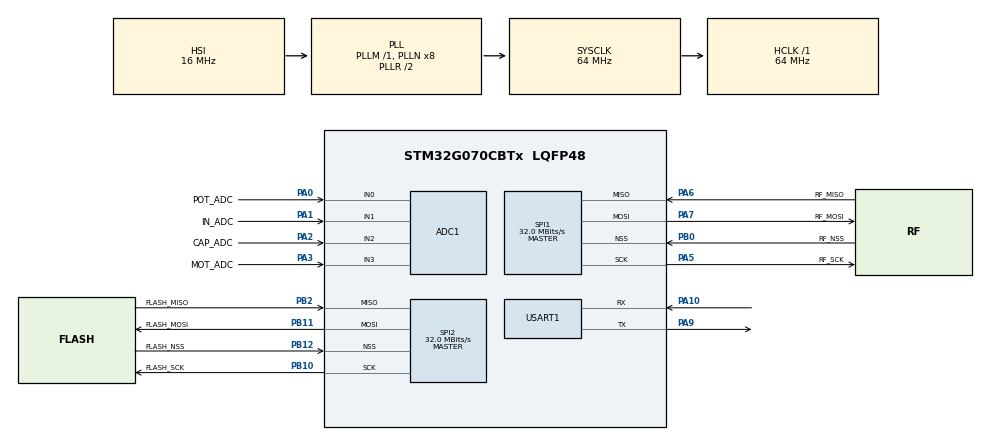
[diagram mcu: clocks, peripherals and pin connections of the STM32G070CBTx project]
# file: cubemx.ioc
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ADC1.AWD1HighThreshold=4095
ADC1.AWD1ITMode=ENABLE
ADC1.ContinuousConvMode=ENABLE
ADC1.DMAContinuousRequests=ENABLE
ADC1.EOCSelection=ADC_EOC_SINGLE_CONV
ADC1.EnableAnalogWatchDog1=true
ADC1.NbrOfConversion=1
ADC1.NbrOfConversionFlag=0
ADC1.Overrun=ADC_OVR_DATA_OVERWRITTEN
ADC1.SamplingTimeCommon1=ADC_SAMPLETIME_160CYCLES_5
ADC1.SelectedChannel=ADC_CHANNEL_0|ADC_CHANNEL_1|ADC_CHANNEL_2|ADC_CHANNEL_3
ADC1.Sequencer=NOT_FULLY_CONFIGURABLE
ADC1.WatchdogMode=ADC_ANALOGWATCHDOG_ALL_REG
ADC1.master=1
Dma.ADC1.0.Direction=DMA_PERIPH_TO_MEMORY
Dma.ADC1.0.EventEnable=DISABLE
Dma.ADC1.0.Instance=DMA1_Channel1
Dma.ADC1.0.MemDataAlignment=DMA_MDATAALIGN_WORD
Dma.ADC1.0.MemInc=DMA_MINC_ENABLE
Dma.ADC1.0.Mode=DMA_CIRCULAR
Dma.ADC1.0.PeriphDataAlignment=DMA_PDATAALIGN_WORD
Dma.ADC1.0.PeriphInc=DMA_PINC_DISABLE
Dma.ADC1.0.Polarity=HAL_DMAMUX_REQ_GEN_RISING
Dma.ADC1.0.Priority=DMA_PRIORITY_LOW
Dma.ADC1.0.RequestNumber=1
Dma.ADC1.0.SignalID=NONE
Dma.ADC1.0.SyncEnable=ENABLE
Dma.ADC1.0.SyncPolarity=HAL_DMAMUX_SYNC_RISING
Dma.ADC1.0.SyncRequestNumber=1
Dma.ADC1.0.SyncSignalID=NONE
Dma.Request0=ADC1
IWDG.Prescaler=IWDG_PRESCALER_256
Mcu.Family=STM32G0
Mcu.Name=STM32G070CBTx
Mcu.Package=LQFP48
NVIC.ADC1_IRQn=true\:0\:0\:false\:false\:true\:true\:true\:true
NVIC.DMA1_Ch4_7_DMAMUX1_OVR_IRQn=true\:0\:0\:false\:false\:true\:false\:true\:true
NVIC.DMA1_Channel1_IRQn=true\:0\:0\:false\:false\:true\:false\:true\:true
NVIC.RTC_TAMP_IRQn=true\:0\:0\:false\:false\:true\:true\:true\:true
NVIC.SPI1_IRQn=true\:0\:0\:false\:false\:true\:true\:true\:true
PA0.GPIO_Label=POT_ADC
PA0.Mode=IN0
PA0.Signal=ADC1_IN0
PA1.GPIO_Label=IN_ADC
PA1.Mode=IN1
PA1.Signal=ADC1_IN1
PA10.Mode=Asynchronous
PA10.Signal=USART1_RX
PA13.Mode=Serial_Wire
PA13.Signal=SYS_SWDIO
PA14-BOOT0.Mode=Serial_Wire
PA14-BOOT0.Signal=SYS_SWCLK
PA2.GPIO_Label=CAP_ADC
PA2.Mode=IN2
PA2.Signal=ADC1_IN2
PA3.GPIO_Label=MOT_ADC
PA3.Mode=IN3
PA3.Signal=ADC1_IN3
PA5.GPIO_Label=RF_SCK
PA5.Mode=Full_Duplex_Master
PA5.Signal=SPI1_SCK
PA6.GPIO_Label=RF_MISO
PA6.Mode=Full_Duplex_Master
PA6.Signal=SPI1_MISO
PA7.GPIO_Label=RF_MOSI
PA7.Mode=Full_Duplex_Master
PA7.Signal=SPI1_MOSI
PA9.Mode=Asynchronous
PA9.Signal=USART1_TX
PB0.GPIO_Label=RF_NSS
PB0.Mode=NSS_Signal_Hard_Input
PB0.Signal=SPI1_NSS
PB10.GPIO_Label=FLASH_SCK
PB10.Mode=Full_Duplex_Master
PB10.Signal=SPI2_SCK
PB11.GPIO_Label=FLASH_MOSI
PB11.Mode=Full_Duplex_Master
PB11.Signal=SPI2_MOSI
PB12.GPIO_Label=FLASH_NSS
PB12.Mode=NSS_Signal_Hard_Input
PB12.Signal=SPI2_NSS
PB2.GPIO_Label=FLASH_MISO
PB2.Mode=Full_Duplex_Master
PB2.Signal=SPI2_MISO
PC14-OSC32_IN\ (PC14).Mode=LSE-External-Oscillator
PC14-OSC32_IN\ (PC14).Signal=RCC_OSC32_IN
PC15-OSC32_OUT\ (PC15).Mode=LSE-External-Oscillator
PC15-OSC32_OUT\ (PC15).Signal=RCC_OSC32_OUT
ProjectManager.HeapSize=0x200
ProjectManager.StackSize=0x400
ProjectManager.TargetToolchain=EWARM V8.50
RCC.ADCFreq_Value=64000000
RCC.AHBFreq_Value=64000000
RCC.CortexFreq_Value=64000000
RCC.EXTERNAL_CLOCK_VALUE=48000
RCC.HCLKFreq_Value=64000000
RCC.HSE_VALUE=8000000
RCC.HSI_VALUE=16000000
RCC.RTCClockSelection=RCC_RTCCLKSOURCE_LSE
RCC.SYSCLKFreq_VALUE=64000000
RCC.SYSCLKSource=RCC_SYSCLKSOURCE_PLLCLK
RCC.VCOOutputFreq_Value=128000000
RTC.Alarm-Alarm\ A=RTC_ALARM_A
RTC.AlarmDateWeekDaySel-Alarm\ A=RTC_ALARMDATEWEEKDAYSEL_WEEKDAY
RTC.Date=24
RTC.Format=RTC_FORMAT_BIN
RTC.HourFormat=RTC_HOURFORMAT_12
RTC.Hours_A-Alarm\ A=1
RTC.Month=RTC_MONTH_FEBRUARY
RTC.WeekDay=RTC_WEEKDAY_TUESDAY
RTC.Year=20
SPI1.CalculateBaudRate=32.0 MBits/s
SPI1.Direction=SPI_DIRECTION_2LINES
SPI1.Mode=SPI_MODE_MASTER
SPI1.VirtualNSS=VM_NSSHARD
SPI1.VirtualType=VM_MASTER
SPI2.CalculateBaudRate=32.0 MBits/s
SPI2.Direction=SPI_DIRECTION_2LINES
SPI2.Mode=SPI_MODE_MASTER
SPI2.VirtualNSS=VM_NSSHARD
SPI2.VirtualType=VM_MASTER
USART1.VirtualMode-Asynchronous=VM_ASYNC
VP_IWDG_VS_IWDG.Mode=IWDG_Activate
VP_RTC_VS_RTC_Activate.Mode=RTC_Enabled
VP_RTC_VS_RTC_Alarm_A_Intern.Mode=Alarm A
VP_RTC_VS_RTC_Calendar.Mode=RTC_Calendar
VP_SYS_VS_DBSignals.Mode=DisableDeadBatterySignals
board=custom

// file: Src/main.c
/* USER CODE BEGIN Header */
/**
  ******************************************************************************
  * @file           : main.c
  * @brief          : Main program body
  ******************************************************************************
  * @attention
  *
  * Copyright (c) 2023 STMicroelectronics.
  * All rights reserved.
  *
  * This software is licensed under terms that can be found in the LICENSE file
  * in the root directory of this software component.
  * If no LICENSE file comes with this software, it is provided AS-IS.
  *
  ******************************************************************************
  */
/* USER CODE END Header */
#include "main.h"
#include "adc.h"
#include "dma.h"
#include "iwdg.h"
#include "rtc.h"
#include "spi.h"
#include "usart.h"
#include "gpio.h"

/* USER CODE BEGIN Includes */
#include <rtthread.h>
#include "drv_common.h"

#define DBG_TAG "main"
#define DBG_LVL DBG_LOG
#include <rtdbg.h>
/* USER CODE END Includes */

void SystemClock_Config(void);

__WEAK int main(void)
{

  /* MCU Configuration--------------------------------------------------------*/

  /* Reset of all peripherals, Initializes the Flash interface and the Systick. */
  HAL_Init();

  /* Configure the system clock */
  SystemClock_Config();

  /* Initialize all configured peripherals */
  MX_GPIO_Init();
  MX_DMA_Init();
  MX_ADC1_Init();
  MX_RTC_Init();
  MX_USART1_UART_Init();
  MX_SPI1_Init();
  MX_SPI2_Init();
  MX_IWDG_Init();

  /* Infinite loop */
  /* USER CODE BEGIN WHILE */
  while (1)
  {

      LOG_D("Hello RT-Thread!");
      rt_thread_mdelay(1000);
    /* USER CODE END WHILE */

  }
}

void SystemClock_Config(void)
{
  RCC_OscInitTypeDef RCC_OscInitStruct = {0};
  RCC_ClkInitTypeDef RCC_ClkInitStruct = {0};
//  RCC_PeriphCLKInitTypeDef PeriphClkInit = {0};

  /** Configure the main internal regulator output voltage
  */
  HAL_PWREx_ControlVoltageScaling(PWR_REGULATOR_VOLTAGE_SCALE1);

  /** Configure LSE Drive Capability
  */
  HAL_PWR_EnableBkUpAccess();
  __HAL_RCC_LSEDRIVE_CONFIG(RCC_LSEDRIVE_LOW);

  /** Initializes the RCC Oscillators according to the specified parameters
  * in the RCC_OscInitTypeDef structure.
  */
  RCC_OscInitStruct.OscillatorType = RCC_OSCILLATORTYPE_HSI|RCC_OSCILLATORTYPE_LSE;
  RCC_OscInitStruct.LSEState = RCC_LSE_ON;
  RCC_OscInitStruct.HSIState = RCC_HSI_ON;
  RCC_OscInitStruct.HSIDiv = RCC_HSI_DIV1;
  RCC_OscInitStruct.HSICalibrationValue = RCC_HSICALIBRATION_DEFAULT;
  RCC_OscInitStruct.PLL.PLLState = RCC_PLL_ON;
  RCC_OscInitStruct.PLL.PLLSource = RCC_PLLSOURCE_HSI;
  RCC_OscInitStruct.PLL.PLLM = RCC_PLLM_DIV1;
  RCC_OscInitStruct.PLL.PLLN = 8;
  RCC_OscInitStruct.PLL.PLLP = RCC_PLLP_DIV2;
  RCC_OscInitStruct.PLL.PLLR = RCC_PLLR_DIV2;
  if (HAL_RCC_OscConfig(&RCC_OscInitStruct) != HAL_OK)
  {
    Error_Handler();
  }

  /** Initializes the CPU, AHB and APB buses clocks
  */
  RCC_ClkInitStruct.ClockType = RCC_CLOCKTYPE_HCLK|RCC_CLOCKTYPE_SYSCLK
                              |RCC_CLOCKTYPE_PCLK1;
  RCC_ClkInitStruct.SYSCLKSource = RCC_SYSCLKSOURCE_PLLCLK;
  RCC_ClkInitStruct.AHBCLKDivider = RCC_SYSCLK_DIV1;
  RCC_ClkInitStruct.APB1CLKDivider = RCC_HCLK_DIV1;

  if (HAL_RCC_ClockConfig(&RCC_ClkInitStruct, FLASH_LATENCY_2) != HAL_OK)
  {
    Error_Handler();
  }

//  PeriphClkInit.PeriphClockSelection = RCC_PERIPHCLK_RTC;     //指定要配置的外设时钟，这里是 RTC 外设时钟
//  PeriphClkInit.RTCClockSelection = RCC_RTCCLKSOURCE_LSE;     //指定 RTC 时钟源，这里选择低速外部时钟（LSE）作为 RTC 时钟源
//  if (HAL_RCCEx_PeriphCLKConfig(&PeriphClkInit) != HAL_OK)
//  {
//    Error_Handler();
//  }
}

//void Error_Handler(void)
//{
  /* USER CODE BEGIN Error_Handler_Debug */
//  /* User can add his own implementation to report the HAL error return state */
//  __disable_irq();
//  while (1)
//  {
//  }
  /* USER CODE END Error_Handler_Debug */
//}
